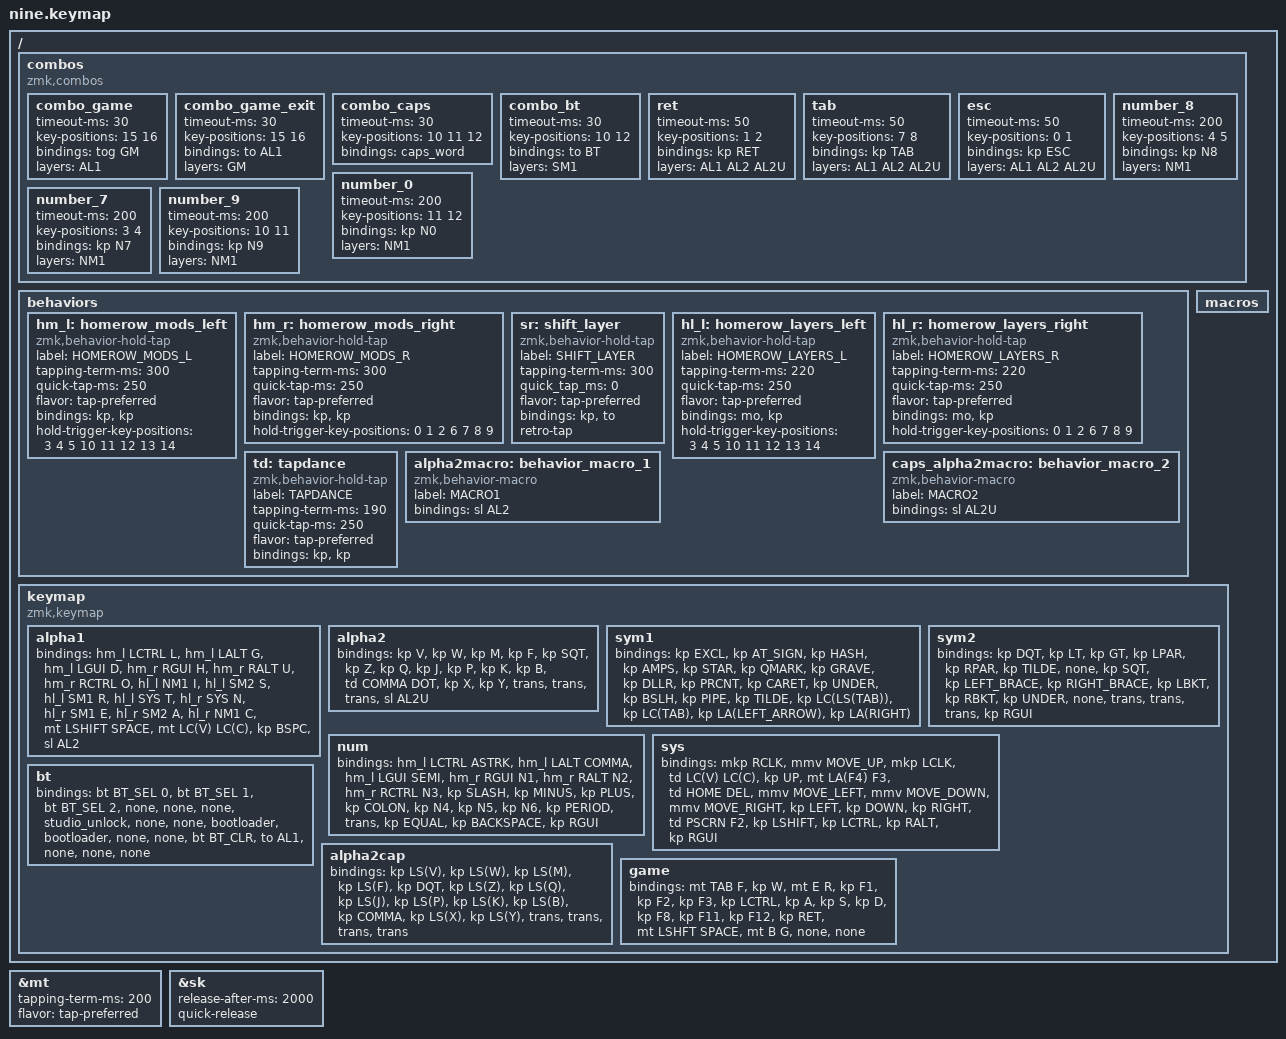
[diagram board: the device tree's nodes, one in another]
/*
 * Copyright (c) 2020 The ZMK Contributors
 *
 * SPDX-License-Identifier: MIT
 *
 */

#include <behaviors/mouse_keys.dtsi>
#include <dt-bindings/zmk/mouse.h>
#include <behaviors.dtsi>
#include <dt-bindings/zmk/bt.h>
#include <dt-bindings/zmk/keys.h>
#include <dt-bindings/zmk/pointing.h>

#define ZMK_MOUSE_DEFAULT_MOVE_VAL 2000  // 600
#define ZMK_MOUSE_DEFAULT_SCRL_VAL 10    // 10

&mt {
    tapping-term-ms = <200>;
    flavor = "tap-preferred";
};

&sk {
    release-after-ms = <2000>;
    quick-release;
};

/* Layers */

#define AL1 0
#define AL2 1
#define SM1 2
#define SM2 3
#define NM1 4
#define SYS 5
#define BT 6
#define AL2U 7
#define GM 8

/ {
    combos {
        compatible = "zmk,combos";

        //combo_sys {
        //	timeout-ms = <30>;
        //	key-positions = <3 4 5>;
        //	bindings = <&tog SYS>;
        // };

        combo_game {
            timeout-ms = <30>;
            key-positions = <15 16>;
            bindings = <&tog GM>;
            layers = <AL1>;
        };

        combo_game_exit {
            timeout-ms = <30>;
            key-positions = <15 16>;
            bindings = <&to AL1>;
            layers = <GM>;
        };

        combo_caps {
            timeout-ms = <30>;
            key-positions = <10 11 12>;
            bindings = <&caps_word>;
        };

        combo_bt {
            timeout-ms = <30>;
            key-positions = <10 12>;
            bindings = <&to BT>;
            layers = <SM1>;
        };

        /*
        bksp {
            timeout-ms = <50>;
            key-positions = <11 12>;
            bindings = <&kp BSPC>;
            layers = <AL1 AL2 AL2U>;
        };
*/

        ret {
            timeout-ms = <50>;
            key-positions = <1 2>;
            bindings = <&kp RET>;
            layers = <AL1 AL2 AL2U>;
        };

        tab {
            timeout-ms = <50>;
            key-positions = <7 8>;
            bindings = <&kp TAB>;
            layers = <AL1 AL2 AL2U>;
        };

        esc {
            timeout-ms = <50>;
            key-positions = <0 1>;
            bindings = <&kp ESC>;
            layers = <AL1 AL2 AL2U>;
        };

        number_8 {
            timeout-ms = <200>;
            key-positions = <4 5>;
            bindings = <&kp N8>;
            layers = <NM1>;
        };

        number_0 {
            timeout-ms = <200>;
            key-positions = <11 12>;
            bindings = <&kp N0>;
            layers = <NM1>;
        };

        number_7 {
            timeout-ms = <200>;
            key-positions = <3 4>;
            bindings = <&kp N7>;
            layers = <NM1>;
        };

        number_9 {
            timeout-ms = <200>;
            key-positions = <10 11>;
            bindings = <&kp N9>;
            layers = <NM1>;
        };
    };

    behaviors {
        hm_l: homerow_mods_left {
            compatible = "zmk,behavior-hold-tap";
            label = "HOMEROW_MODS_L";
            #binding-cells = <2>;
            tapping-term-ms = <300>;
            quick-tap-ms = <250>;
            flavor = "tap-preferred";
            bindings = <&kp>, <&kp>;

            hold-trigger-key-positions = <3 4 5 10 11 12 13 14>; // right hand
        };

        hm_r: homerow_mods_right {
            compatible = "zmk,behavior-hold-tap";
            label = "HOMEROW_MODS_R";
            #binding-cells = <2>;
            tapping-term-ms = <300>;
            quick-tap-ms = <250>;
            flavor = "tap-preferred";
            bindings = <&kp>, <&kp>;

            hold-trigger-key-positions = <0 1 2 6 7 8 9>; // left hand
        };

        sr: shift_layer {
            compatible = "zmk,behavior-hold-tap";
            label = "SHIFT_LAYER";
            #binding-cells = <2>;
            tapping-term-ms = <300>;
            quick_tap_ms = <0>;
            flavor = "tap-preferred";
            bindings = <&kp>, <&to>;

            retro-tap;
        };

        hl_l: homerow_layers_left {
            compatible = "zmk,behavior-hold-tap";
            label = "HOMEROW_LAYERS_L";
            #binding-cells = <2>;
            tapping-term-ms = <220>;
            quick-tap-ms = <250>;
            flavor = "tap-preferred";
            bindings = <&mo>, <&kp>;

            hold-trigger-key-positions = <3 4 5 10 11 12 13 14>; // right hand
        };

        hl_r: homerow_layers_right {
            compatible = "zmk,behavior-hold-tap";
            label = "HOMEROW_LAYERS_R";
            #binding-cells = <2>;
            tapping-term-ms = <220>;
            quick-tap-ms = <250>;
            flavor = "tap-preferred";
            bindings = <&mo>, <&kp>;

            hold-trigger-key-positions = <0 1 2 6 7 8 9>; // left hand
        };

        td: tapdance {
            compatible = "zmk,behavior-hold-tap";
            label = "TAPDANCE";
            #binding-cells = <2>;
            tapping-term-ms = <190>;
            quick-tap-ms = <250>;
            flavor = "tap-preferred";
            bindings = <&kp>, <&kp>;
        };

        alpha2macro: behavior_macro_1 {
            compatible = "zmk,behavior-macro";
            label = "MACRO1";
            #binding-cells = <0>;
            bindings = <&sl AL2>;
        };

        caps_alpha2macro: behavior_macro_2 {
            compatible = "zmk,behavior-macro";
            label = "MACRO2";
            #binding-cells = <0>;
            bindings = <&sl AL2U>;
        };
    };

    //			00	01	02			03	04	05
    //		06	07	08	09			10	11	12	13
    //					14	15	16	17

    macros {
    };

    keymap {
        compatible = "zmk,keymap";

        alpha1 {
            bindings = <
&hm_l LCTRL L  &hm_l LALT G  &hm_l LGUI D  &hm_r RGUI H  &hm_r RALT U  &hm_r RCTRL O  &hl_l NM1 I  &hl_l SM2 S  &hl_l SM1 R  &hl_l SYS T  &hl_r SYS N  &hl_r SM1 E  &hl_r SM2 A  &hl_r NM1 C  &mt LSHIFT SPACE  &mt LC(V) LC(C)  &kp BSPC  &sl AL2
            >;
        };

        alpha2 {
            bindings = <
&kp V  &kp W  &kp M  &kp F  &kp SQT  &kp Z  &kp Q  &kp J  &kp P  &kp K  &kp B  &td COMMA DOT  &kp X  &kp Y  &trans  &trans  &trans  &sl AL2U
            >;
        };

        sym1 {
            bindings = <
&kp EXCL  &kp AT_SIGN  &kp HASH  &kp AMPS  &kp STAR  &kp QMARK  &kp GRAVE  &kp DLLR  &kp PRCNT  &kp CARET  &kp UNDER  &kp BSLH  &kp PIPE  &kp TILDE  &kp LC(LS(TAB))  &kp LC(TAB)  &kp LA(LEFT_ARROW)  &kp LA(RIGHT)
            >;
        };

        sym2 {
            bindings = <
&kp DQT  &kp LT  &kp GT  &kp LPAR  &kp RPAR  &kp TILDE  &none  &kp SQT  &kp LEFT_BRACE  &kp RIGHT_BRACE  &kp LBKT  &kp RBKT  &kp UNDER  &none  &trans  &trans  &trans  &kp RGUI
            >;
        };

        num {
            bindings = <
&hm_l LCTRL ASTRK  &hm_l LALT COMMA  &hm_l LGUI SEMI  &hm_r RGUI N1  &hm_r RALT N2  &hm_r RCTRL N3  &kp SLASH  &kp MINUS  &kp PLUS  &kp COLON  &kp N4  &kp N5  &kp N6  &kp PERIOD  &trans  &kp EQUAL  &kp BACKSPACE  &kp RGUI
            >;
        };

        sys {
            bindings = <
&mkp RCLK  &mmv MOVE_UP  &mkp LCLK  &td LC(V) LC(C)  &kp UP  &mt LA(F4) F3  &td HOME DEL  &mmv MOVE_LEFT  &mmv MOVE_DOWN  &mmv MOVE_RIGHT  &kp LEFT  &kp DOWN  &kp RIGHT  &td PSCRN F2  &kp LSHIFT  &kp LCTRL  &kp RALT  &kp RGUI
            >;
        };

        bt {
            bindings = <
&bt BT_SEL 0  &bt BT_SEL 1  &bt BT_SEL 2  &none  &none  &none  &studio_unlock  &none  &none  &bootloader  &bootloader  &none  &none  &bt BT_CLR  &to AL1  &none  &none  &none
            >;
        };

        alpha2cap {
            bindings = <
&kp LS(V)  &kp LS(W)  &kp LS(M)  &kp LS(F)  &kp DQT  &kp LS(Z)  &kp LS(Q)  &kp LS(J)  &kp LS(P)  &kp LS(K)  &kp LS(B)  &kp COMMA  &kp LS(X)  &kp LS(Y)  &trans  &trans  &trans  &trans
            >;
        };

        game {
            bindings = <
&mt TAB F  &kp W  &mt E R  &kp F1  &kp F2  &kp F3  &kp LCTRL  &kp A  &kp S  &kp D  &kp F8  &kp F11  &kp F12  &kp RET  &mt LSHFT SPACE  &mt B G  &none  &none
            >;
        };
    };
};
